# STM32H7B3ZIT6Q register map
File version: 1.0
Registers are 32-bit, access not given, reset 0x0 unless marked. A register's access mark holds for its fields unless they carry their own. Offsets are from the block's base; [hi:lo] are bit positions; {n}, {i} and the like mark numbered series.

## RCC
Base 0x58024400
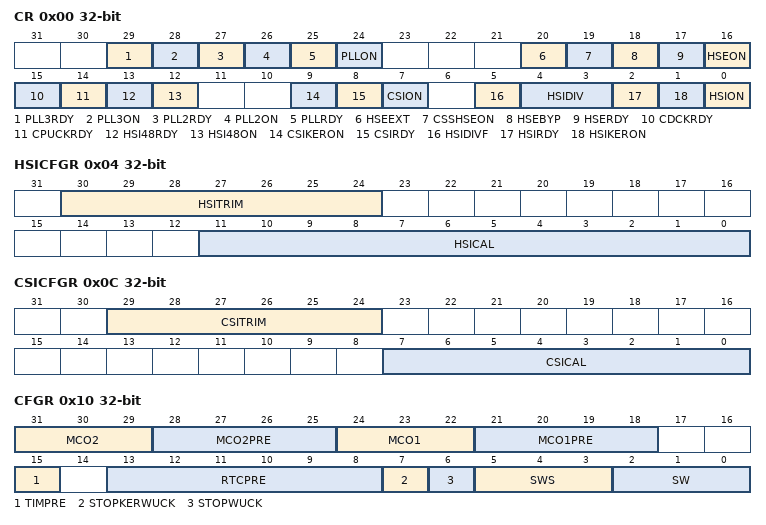
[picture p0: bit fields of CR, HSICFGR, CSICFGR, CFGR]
0x00 CR
  [29] PLL3RDY, [28] PLL3ON, [27] PLL2RDY, [26] PLL2ON, [25] PLLRDY, [24] PLLON, [20] HSEEXT, [19] CSSHSEON, [18] HSEBYP, [17] HSERDY, [16] HSEON, [15] CDCKRDY, [14] CPUCKRDY, [13] HSI48RDY, [12] HSI48ON, [9] CSIKERON, [8] CSIRDY, [7] CSION, [5] HSIDIVF, [4:3] HSIDIV, [2] HSIRDY, [1] HSIKERON, [0] HSION
0x04 HSICFGR
  [30:24] HSITRIM, [11:0] HSICAL
0x08 CRRCR
  [9:0] HSI48CAL
0x0C CSICFGR
  [29:24] CSITRIM, [7:0] CSICAL
0x10 CFGR
  [31:29] MCO2, [28:25] MCO2PRE, [24:22] MCO1, [21:18] MCO1PRE, [15] TIMPRE, [13:8] RTCPRE, [7] STOPKERWUCK, [6] STOPWUCK, [5:3] SWS, [2:0] SW
0x18 CDCFGR1
  [11] CDCPRE_DIV2, [11:10] CDCPRE_DIV64, [11:9] CDCPRE_DIV8, [11:8] CDCPRE_DIV512, [6] CDPPRE_DIV2, [6:5] CDPPRE_DIV8, [6:4] CDPPRE_DIV4, [3] HPRE_DIV2, [3:2] HPRE_DIV64, [3:1] HPRE_DIV8, [3:0] HPRE_DIV512
0x1C CDCFGR2
  [10] CDPPRE2_DIV2, [10:9] CDPPRE2_DIV8, [10:8] CDPPRE2_DIV4, [6] CDPPRE1_DIV2, [6:5] CDPPRE1_DIV8, [6:4] CDPPRE1_DIV4
0x20 SRDCFGR
  [6] SRDPPRE_DIV2, [6:5] SRDPPRE_DIV8, [6:4] SRDPPRE_DIV4
0x28 PLLCKSELR
  [25:20] DIVM3, [17:12] DIVM2, [9:4] DIVM1, [1] PLLSRC_HSE, [1:0] PLLSRC_NONE
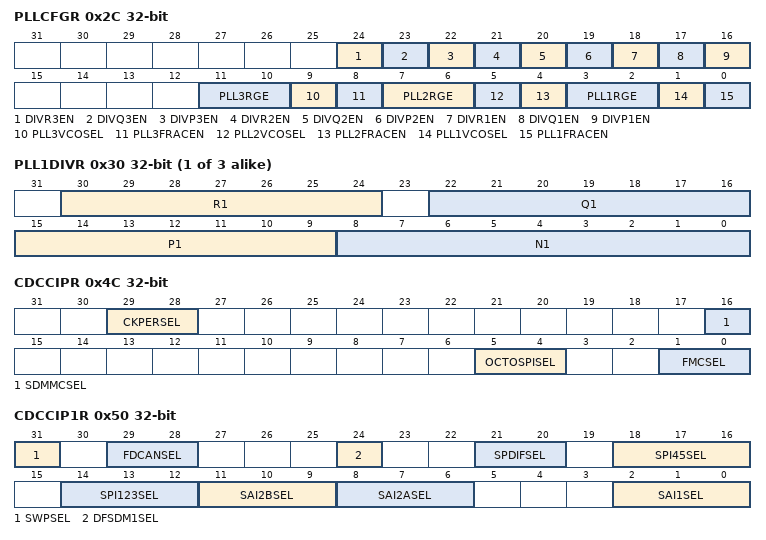
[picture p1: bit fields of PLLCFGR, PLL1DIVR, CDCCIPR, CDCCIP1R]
0x2C PLLCFGR
  [24] DIVR3EN, [23] DIVQ3EN, [22] DIVP3EN, [21] DIVR2EN, [20] DIVQ2EN, [19] DIVP2EN, [18] DIVR1EN, [17] DIVQ1EN, [16] DIVP1EN, [11:10] PLL3RGE, [9] PLL3VCOSEL, [8] PLL3FRACEN, [7:6] PLL2RGE, [5] PLL2VCOSEL, [4] PLL2FRACEN, [3:2] PLL1RGE, [1] PLL1VCOSEL, [0] PLL1FRACEN
{0x28+8i} PLL{i}DIVR (i=1..3)
  [30:24] R{i}, [22:16] Q{i}, [15:9] P{i}, [8:0] N{i}
{0x2C+8i} PLL{i}FRACR (i=1..3)
  [15:3] FRACN{i}
0x4C CDCCIPR
  [29:28] CKPERSEL, [16] SDMMCSEL, [5:4] OCTOSPISEL, [1:0] FMCSEL
0x50 CDCCIP1R
  [31] SWPSEL, [29:28] FDCANSEL, [24] DFSDM1SEL, [21:20] SPDIFSEL, [18:16] SPI45SEL, [14:12] SPI123SEL, [11:9] SAI2BSEL, [8:6] SAI2ASEL, [2:0] SAI1SEL
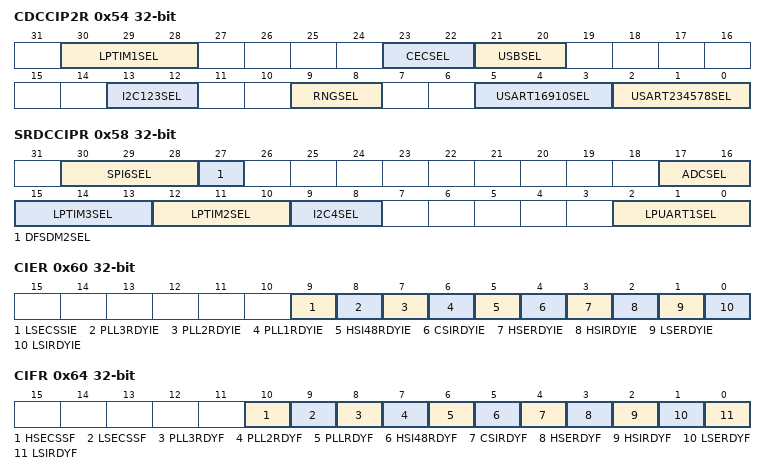
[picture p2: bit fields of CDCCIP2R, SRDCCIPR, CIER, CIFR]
0x54 CDCCIP2R
  [30:28] LPTIM1SEL, [23:22] CECSEL, [21:20] USBSEL, [13:12] I2C123SEL, [9:8] RNGSEL, [5:3] USART16910SEL, [2:0] USART234578SEL
0x58 SRDCCIPR
  [30:28] SPI6SEL, [27] DFSDM2SEL, [17:16] ADCSEL, [15:13] LPTIM3SEL, [12:10] LPTIM2SEL, [9:8] I2C4SEL, [2:0] LPUART1SEL
0x60 CIER
  [9] LSECSSIE, [8] PLL3RDYIE, [7] PLL2RDYIE, [6] PLL1RDYIE, [5] HSI48RDYIE, [4] CSIRDYIE, [3] HSERDYIE, [2] HSIRDYIE, [1] LSERDYIE, [0] LSIRDYIE
0x64 CIFR
  [10] HSECSSF, [9] LSECSSF, [8] PLL3RDYF, [7] PLL2RDYF, [6] PLLRDYF, [5] HSI48RDYF, [4] CSIRDYF, [3] HSERDYF, [2] HSIRDYF, [1] LSERDYF, [0] LSIRDYF
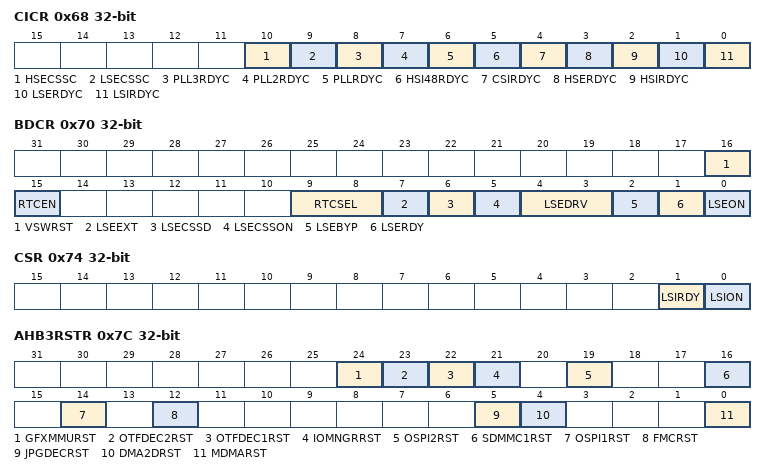
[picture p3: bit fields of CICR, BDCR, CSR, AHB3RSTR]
0x68 CICR
  [10] HSECSSC, [9] LSECSSC, [8] PLL3RDYC, [7] PLL2RDYC, [6] PLLRDYC, [5] HSI48RDYC, [4] CSIRDYC, [3] HSERDYC, [2] HSIRDYC, [1] LSERDYC, [0] LSIRDYC
0x70 BDCR
  [16] VSWRST, [15] RTCEN, [9:8] RTCSEL, [7] LSEEXT, [6] LSECSSD, [5] LSECSSON, [4:3] LSEDRV, [2] LSEBYP, [1] LSERDY, [0] LSEON
0x74 CSR
  [1] LSIRDY, [0] LSION
0x7C AHB3RSTR
  [24] GFXMMURST, [23] OTFDEC2RST, [22] OTFDEC1RST, [21] IOMNGRRST, [19] OSPI2RST, [16] SDMMC1RST, [14] OSPI1RST, [12] FMCRST, [5] JPGDECRST, [4] DMA2DRST, [0] MDMARST
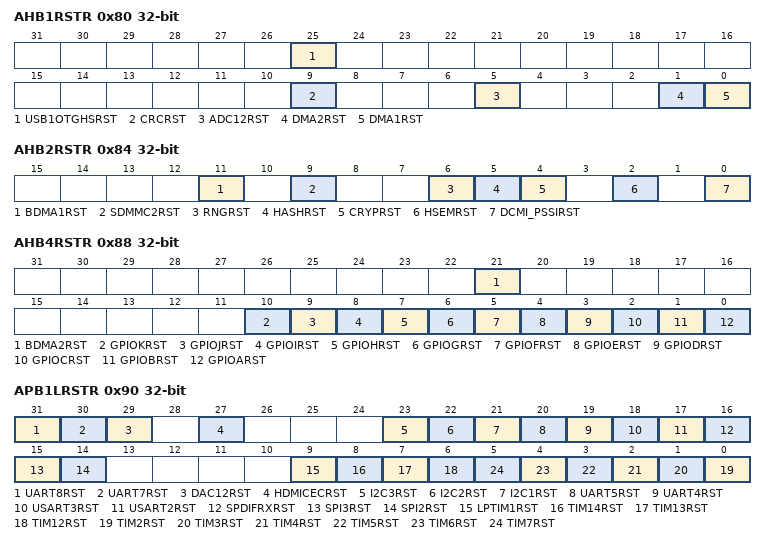
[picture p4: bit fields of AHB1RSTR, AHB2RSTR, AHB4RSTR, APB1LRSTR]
0x80 AHB1RSTR
  [25] USB1OTGHSRST, [9] CRCRST, [5] ADC12RST, [1] DMA2RST, [0] DMA1RST
0x84 AHB2RSTR
  [11] BDMA1RST, [9] SDMMC2RST, [6] RNGRST, [5] HASHRST, [4] CRYPRST, [2] HSEMRST, [0] DCMI_PSSIRST
0x88 AHB4RSTR
  [21] BDMA2RST, [10] GPIOKRST, [9] GPIOJRST, [8] GPIOIRST, [7] GPIOHRST, [6] GPIOGRST, [5] GPIOFRST, [4] GPIOERST, [3] GPIODRST, [2] GPIOCRST, [1] GPIOBRST, [0] GPIOARST
0x8C APB3RSTR
  [3] LTDCRST
0x90 APB1LRSTR
  [31] UART8RST, [30] UART7RST, [29] DAC12RST, [27] HDMICECRST, [23] I2C3RST, [22] I2C2RST, [21] I2C1RST, [20] UART5RST, [19] UART4RST, [18] USART3RST, [17] USART2RST, [16] SPDIFRXRST, [15] SPI3RST, [14] SPI2RST, [9] LPTIM1RST, [8] TIM14RST, [7] TIM13RST, [6] TIM12RST, [n-2] TIM{n}RST (n=2..7)
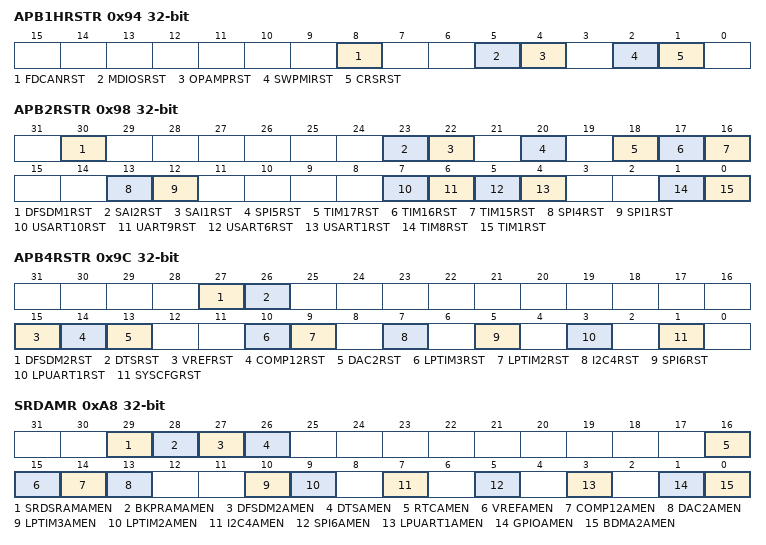
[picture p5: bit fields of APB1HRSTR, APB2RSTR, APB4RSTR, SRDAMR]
0x94 APB1HRSTR
  [8] FDCANRST, [5] MDIOSRST, [4] OPAMPRST, [2] SWPMIRST, [1] CRSRST
0x98 APB2RSTR
  [30] DFSDM1RST, [23] SAI2RST, [22] SAI1RST, [20] SPI5RST, [18] TIM17RST, [17] TIM16RST, [16] TIM15RST, [13] SPI4RST, [12] SPI1RST, [7] USART10RST, [6] UART9RST, [5] USART6RST, [4] USART1RST, [1] TIM8RST, [0] TIM1RST
0x9C APB4RSTR
  [27] DFSDM2RST, [26] DTSRST, [15] VREFRST, [14] COMP12RST, [13] DAC2RST, [10] LPTIM3RST, [9] LPTIM2RST, [7] I2C4RST, [5] SPI6RST, [3] LPUART1RST, [1] SYSCFGRST
0xA8 SRDAMR
  [29] SRDSRAMAMEN, [28] BKPRAMAMEN, [27] DFSDM2AMEN, [26] DTSAMEN, [16] RTCAMEN, [15] VREFAMEN, [14] COMP12AMEN, [13] DAC2AMEN, [10] LPTIM3AMEN, [9] LPTIM2AMEN, [7] I2C4AMEN, [5] SPI6AMEN, [3] LPUART1AMEN, [1] GPIOAMEN, [0] BDMA2AMEN
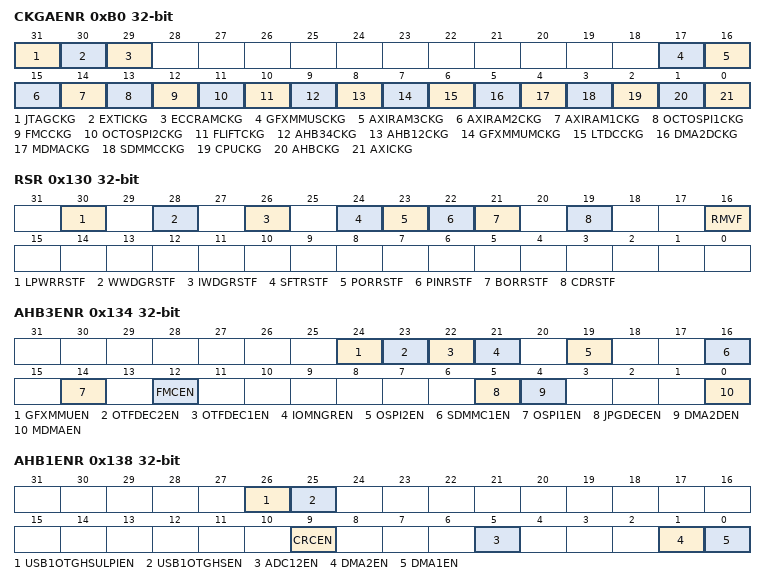
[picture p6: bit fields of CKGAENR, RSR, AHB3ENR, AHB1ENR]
0xB0 CKGAENR
  [31] JTAGCKG, [30] EXTICKG, [29] ECCRAMCKG, [17] GFXMMUSCKG, [16] AXIRAM3CKG, [15] AXIRAM2CKG, [14] AXIRAM1CKG, [13] OCTOSPI1CKG, [12] FMCCKG, [11] OCTOSPI2CKG, [10] FLIFTCKG, [9] AHB34CKG, [8] AHB12CKG, [7] GFXMMUMCKG, [6] LTDCCKG, [5] DMA2DCKG, [4] MDMACKG, [3] SDMMCCKG, [2] CPUCKG, [1] AHBCKG, [0] AXICKG
0x130 RSR
  [30] LPWRRSTF, [28] WWDGRSTF, [26] IWDGRSTF, [24] SFTRSTF, [23] PORRSTF, [22] PINRSTF, [21] BORRSTF, [19] CDRSTF, [16] RMVF
0x134 AHB3ENR
  [24] GFXMMUEN, [23] OTFDEC2EN, [22] OTFDEC1EN, [21] IOMNGREN, [19] OSPI2EN, [16] SDMMC1EN, [14] OSPI1EN, [12] FMCEN, [5] JPGDECEN, [4] DMA2DEN, [0] MDMAEN
0x138 AHB1ENR
  [26] USB1OTGHSULPIEN, [25] USB1OTGHSEN, [9] CRCEN, [5] ADC12EN, [1] DMA2EN, [0] DMA1EN
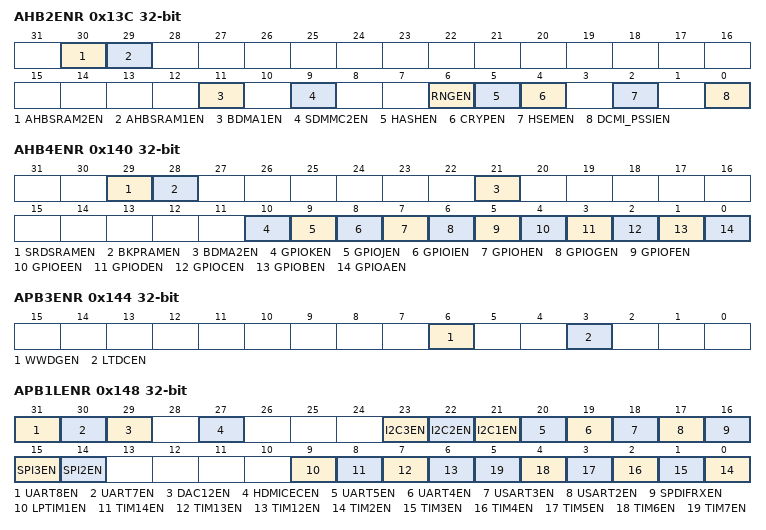
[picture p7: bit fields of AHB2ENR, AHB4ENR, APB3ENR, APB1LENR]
0x13C AHB2ENR
  [30] AHBSRAM2EN, [29] AHBSRAM1EN, [11] BDMA1EN, [9] SDMMC2EN, [6] RNGEN, [5] HASHEN, [4] CRYPEN, [2] HSEMEN, [0] DCMI_PSSIEN
0x140 AHB4ENR
  [29] SRDSRAMEN, [28] BKPRAMEN, [21] BDMA2EN, [10] GPIOKEN, [9] GPIOJEN, [8] GPIOIEN, [7] GPIOHEN, [6] GPIOGEN, [5] GPIOFEN, [4] GPIOEEN, [3] GPIODEN, [2] GPIOCEN, [1] GPIOBEN, [0] GPIOAEN
0x144 APB3ENR
  [6] WWDGEN, [3] LTDCEN
0x148 APB1LENR
  [31] UART8EN, [30] UART7EN, [29] DAC12EN, [27] HDMICECEN, [23] I2C3EN, [22] I2C2EN, [21] I2C1EN, [20] UART5EN, [19] UART4EN, [18] USART3EN, [17] USART2EN, [16] SPDIFRXEN, [15] SPI3EN, [14] SPI2EN, [9] LPTIM1EN, [8] TIM14EN, [7] TIM13EN, [6] TIM12EN, [n-2] TIM{n}EN (n=2..7)
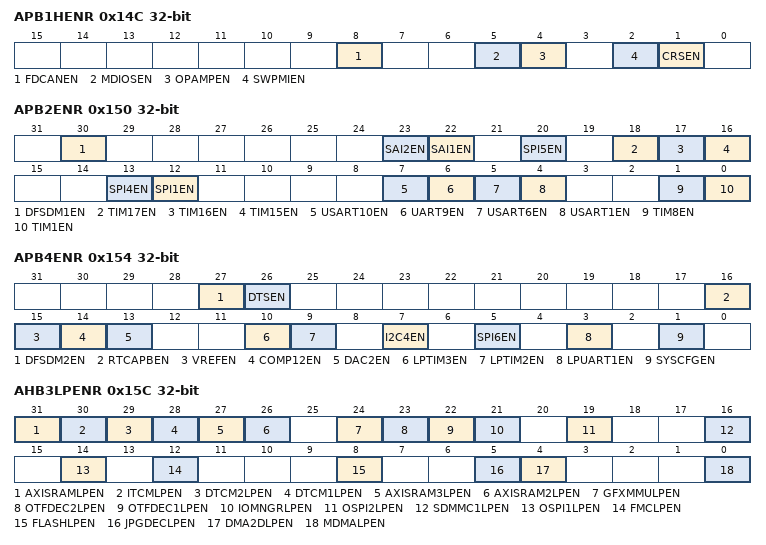
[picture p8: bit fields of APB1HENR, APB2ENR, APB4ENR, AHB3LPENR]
0x14C APB1HENR
  [8] FDCANEN, [5] MDIOSEN, [4] OPAMPEN, [2] SWPMIEN, [1] CRSEN
0x150 APB2ENR
  [30] DFSDM1EN, [23] SAI2EN, [22] SAI1EN, [20] SPI5EN, [18] TIM17EN, [17] TIM16EN, [16] TIM15EN, [13] SPI4EN, [12] SPI1EN, [7] USART10EN, [6] UART9EN, [5] USART6EN, [4] USART1EN, [1] TIM8EN, [0] TIM1EN
0x154 APB4ENR
  [27] DFSDM2EN, [26] DTSEN, [16] RTCAPBEN, [15] VREFEN, [14] COMP12EN, [13] DAC2EN, [10] LPTIM3EN, [9] LPTIM2EN, [7] I2C4EN, [5] SPI6EN, [3] LPUART1EN, [1] SYSCFGEN
0x15C AHB3LPENR
  [31] AXISRAMLPEN, [30] ITCMLPEN, [29] DTCM2LPEN, [28] DTCM1LPEN, [27] AXISRAM3LPEN, [26] AXISRAM2LPEN, [24] GFXMMULPEN, [23] OTFDEC2LPEN, [22] OTFDEC1LPEN, [21] IOMNGRLPEN, [19] OSPI2LPEN, [16] SDMMC1LPEN, [14] OSPI1LPEN, [12] FMCLPEN, [8] FLASHLPEN, [5] JPGDECLPEN, [4] DMA2DLPEN, [0] MDMALPEN
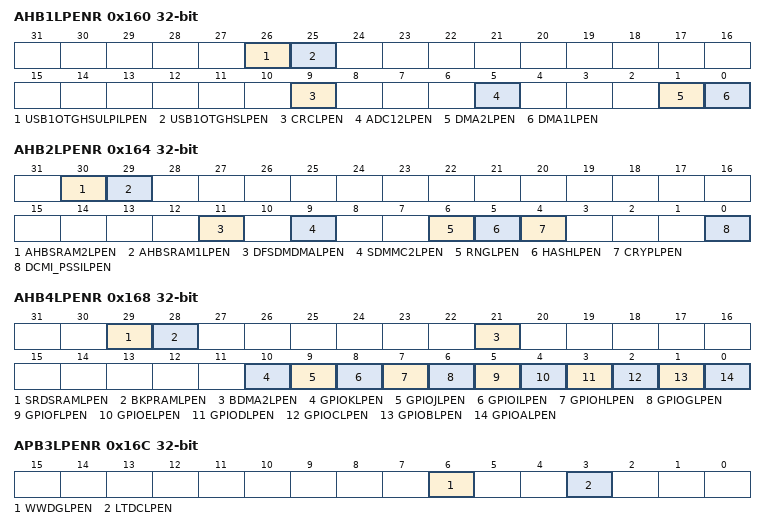
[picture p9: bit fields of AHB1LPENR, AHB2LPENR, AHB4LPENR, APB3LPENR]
0x160 AHB1LPENR
  [26] USB1OTGHSULPILPEN, [25] USB1OTGHSLPEN, [9] CRCLPEN, [5] ADC12LPEN, [1] DMA2LPEN, [0] DMA1LPEN
0x164 AHB2LPENR
  [30] AHBSRAM2LPEN, [29] AHBSRAM1LPEN, [11] DFSDMDMALPEN, [9] SDMMC2LPEN, [6] RNGLPEN, [5] HASHLPEN, [4] CRYPLPEN, [0] DCMI_PSSILPEN
0x168 AHB4LPENR
  [29] SRDSRAMLPEN, [28] BKPRAMLPEN, [21] BDMA2LPEN, [10] GPIOKLPEN, [9] GPIOJLPEN, [8] GPIOILPEN, [7] GPIOHLPEN, [6] GPIOGLPEN, [5] GPIOFLPEN, [4] GPIOELPEN, [3] GPIODLPEN, [2] GPIOCLPEN, [1] GPIOBLPEN, [0] GPIOALPEN
0x16C APB3LPENR
  [6] WWDGLPEN, [3] LTDCLPEN
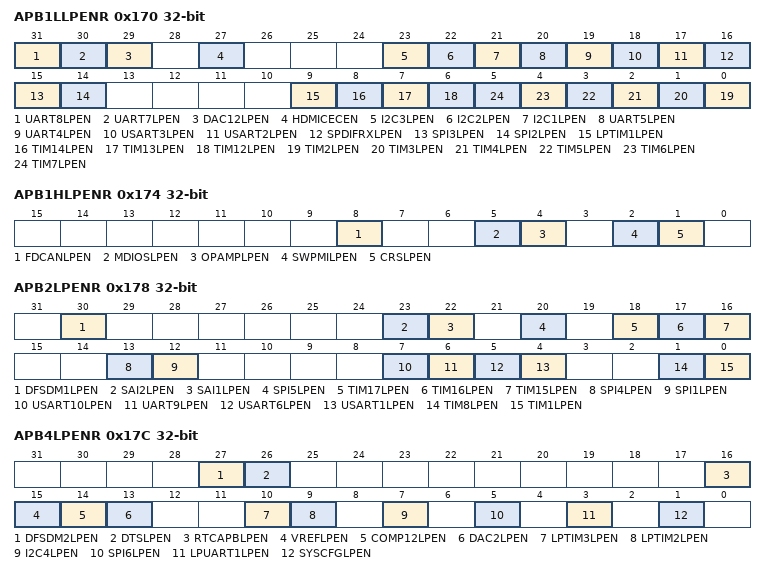
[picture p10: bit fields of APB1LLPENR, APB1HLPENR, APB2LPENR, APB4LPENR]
0x170 APB1LLPENR
  [31] UART8LPEN, [30] UART7LPEN, [29] DAC12LPEN, [27] HDMICECEN, [23] I2C3LPEN, [22] I2C2LPEN, [21] I2C1LPEN, [20] UART5LPEN, [19] UART4LPEN, [18] USART3LPEN, [17] USART2LPEN, [16] SPDIFRXLPEN, [15] SPI3LPEN, [14] SPI2LPEN, [9] LPTIM1LPEN, [8] TIM14LPEN, [7] TIM13LPEN, [6] TIM12LPEN, [n-2] TIM{n}LPEN (n=2..7)
0x174 APB1HLPENR
  [8] FDCANLPEN, [5] MDIOSLPEN, [4] OPAMPLPEN, [2] SWPMILPEN, [1] CRSLPEN
0x178 APB2LPENR
  [30] DFSDM1LPEN, [23] SAI2LPEN, [22] SAI1LPEN, [20] SPI5LPEN, [18] TIM17LPEN, [17] TIM16LPEN, [16] TIM15LPEN, [13] SPI4LPEN, [12] SPI1LPEN, [7] USART10LPEN, [6] UART9LPEN, [5] USART6LPEN, [4] USART1LPEN, [1] TIM8LPEN, [0] TIM1LPEN
0x17C APB4LPENR
  [27] DFSDM2LPEN, [26] DTSLPEN, [16] RTCAPBLPEN, [15] VREFLPEN, [14] COMP12LPEN, [13] DAC2LPEN, [10] LPTIM3LPEN, [9] LPTIM2LPEN, [7] I2C4LPEN, [5] SPI6LPEN, [3] LPUART1LPEN, [1] SYSCFGLPEN
